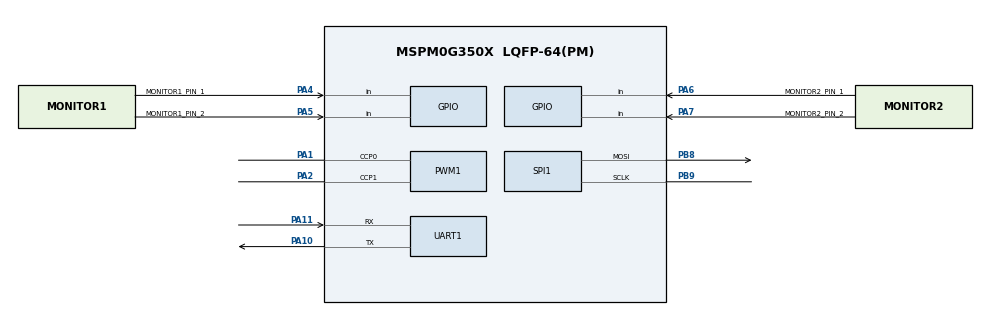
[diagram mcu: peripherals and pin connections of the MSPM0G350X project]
/**
 * These arguments were used when this file was generated. They will be automatically applied on subsequent loads
 * via the GUI or CLI. Run CLI with '--help' for additional information on how to override these arguments.
 * @cliArgs --device "MSPM0G350X" --package "LQFP-64(PM)" --part "Default" --product "mspm0_sdk@2.01.00.03"
 * @versions {"tool":"1.20.0+3587"}
 */

/**
 * Import the modules used in this configuration.
 */
const GPIO   = scripting.addModule("/ti/driverlib/GPIO", {}, false);
const GPIO1  = GPIO.addInstance();
const GPIO2  = GPIO.addInstance();
const GPIO3  = GPIO.addInstance();
const GPIO4  = GPIO.addInstance();
const GPIO5  = GPIO.addInstance();
const PWM    = scripting.addModule("/ti/driverlib/PWM", {}, false);
const PWM1   = PWM.addInstance();
const SPI    = scripting.addModule("/ti/driverlib/SPI", {}, false);
const SPI1   = SPI.addInstance();
const SYSCTL = scripting.addModule("/ti/driverlib/SYSCTL");
const TIMER  = scripting.addModule("/ti/driverlib/TIMER", {}, false);
const TIMER1 = TIMER.addInstance();
const UART   = scripting.addModule("/ti/driverlib/UART", {}, false);
const UART1  = UART.addInstance();

/**
 * Write custom configuration values to the imported modules.
 */
GPIO1.$name                          = "GPIO_LED";
GPIO1.associatedPins[0].$name        = "LED";
GPIO1.associatedPins[0].assignedPort = "PORTA";
GPIO1.associatedPins[0].assignedPin  = "3";

const Board = scripting.addModule("/ti/driverlib/Board", {}, false);

GPIO2.$name                          = "GPIO_OLED";
GPIO2.associatedPins.create(2);
GPIO2.associatedPins[0].$name        = "PIN_SCL";
GPIO2.associatedPins[0].assignedPort = "PORTA";
GPIO2.associatedPins[0].assignedPin  = "12";
GPIO2.associatedPins[1].$name        = "PIN_SDA";
GPIO2.associatedPins[1].assignedPort = "PORTA";
GPIO2.associatedPins[1].assignedPin  = "13";

GPIO3.$name                          = "GPIO_LCD";
GPIO3.associatedPins.create(4);
GPIO3.associatedPins[0].assignedPort = "PORTA";
GPIO3.associatedPins[0].assignedPin  = "27";
GPIO3.associatedPins[0].$name        = "ST7789_RST";
GPIO3.associatedPins[0].initialValue = "SET";
GPIO3.associatedPins[1].$name        = "ST7789_A0";
GPIO3.associatedPins[1].assignedPort = "PORTA";
GPIO3.associatedPins[1].assignedPin  = "26";
GPIO3.associatedPins[1].initialValue = "SET";
GPIO3.associatedPins[2].$name        = "ST7789_CS";
GPIO3.associatedPins[2].assignedPort = "PORTA";
GPIO3.associatedPins[2].assignedPin  = "25";
GPIO3.associatedPins[2].initialValue = "SET";
GPIO3.associatedPins[3].$name        = "ST7789_BL";
GPIO3.associatedPins[3].assignedPort = "PORTA";
GPIO3.associatedPins[3].assignedPin  = "24";
GPIO3.associatedPins[3].initialValue = "SET";

GPIO4.$name                          = "GPIO_SPI_OLED";
GPIO4.associatedPins.create(4);
GPIO4.associatedPins[0].$name        = "CLK";
GPIO4.associatedPins[0].assignedPort = "PORTA";
GPIO4.associatedPins[0].assignedPin  = "14";
GPIO4.associatedPins[1].$name        = "SDA";
GPIO4.associatedPins[1].assignedPort = "PORTA";
GPIO4.associatedPins[1].assignedPin  = "15";
GPIO4.associatedPins[2].$name        = "CS";
GPIO4.associatedPins[2].assignedPort = "PORTA";
GPIO4.associatedPins[2].assignedPin  = "16";
GPIO4.associatedPins[3].$name        = "DC";
GPIO4.associatedPins[3].assignedPort = "PORTA";
GPIO4.associatedPins[3].assignedPin  = "17";

GPIO5.$name                         = "GPIO_ENCODER";
GPIO5.associatedPins.create(4);
GPIO5.associatedPins[0].direction   = "INPUT";
GPIO5.associatedPins[0].interruptEn = true;
GPIO5.associatedPins[0].polarity    = "RISE";
GPIO5.associatedPins[0].$name       = "MONITOR1_PIN_1";
GPIO5.associatedPins[0].pin.$assign = "PA4";
GPIO5.associatedPins[1].$name       = "MONITOR1_PIN_2";
GPIO5.associatedPins[1].direction   = "INPUT";
GPIO5.associatedPins[1].interruptEn = true;
GPIO5.associatedPins[1].polarity    = "RISE";
GPIO5.associatedPins[1].pin.$assign = "PA5";
GPIO5.associatedPins[2].$name       = "MONITOR2_PIN_1";
GPIO5.associatedPins[2].direction   = "INPUT";
GPIO5.associatedPins[2].interruptEn = true;
GPIO5.associatedPins[2].polarity    = "RISE";
GPIO5.associatedPins[2].pin.$assign = "PA6";
GPIO5.associatedPins[3].$name       = "MONITOR2_PIN_2";
GPIO5.associatedPins[3].direction   = "INPUT";
GPIO5.associatedPins[3].interruptEn = true;
GPIO5.associatedPins[3].polarity    = "RISE";
GPIO5.associatedPins[3].pin.$assign = "PA7";

PWM1.$name                      = "PWM_0";
PWM1.clockPrescale              = 32;
PWM1.pwmMode                    = "EDGE_ALIGN_UP";
PWM1.peripheral.ccp0Pin.$assign = "PA1";
PWM1.peripheral.ccp1Pin.$assign = "PA2";
PWM1.PWM_CHANNEL_0.$name        = "ti_driverlib_pwm_PWMTimerCC0";
PWM1.PWM_CHANNEL_0.dutyCycle    = 50;
PWM1.PWM_CHANNEL_1.$name        = "ti_driverlib_pwm_PWMTimerCC1";
PWM1.PWM_CHANNEL_1.dutyCycle    = 30;
PWM1.ccp0PinConfig.$name        = "ti_driverlib_gpio_GPIOPinGeneric4";
PWM1.ccp1PinConfig.$name        = "ti_driverlib_gpio_GPIOPinGeneric5";

SPI1.$name                              = "SPI1";
SPI1.phase                              = "1";
SPI1.frameFormat                        = "MOTO3";
SPI1.polarity                           = "1";
SPI1.direction                          = "PICO";
SPI1.peripheral.sclkPin.$assign         = "PB9";
SPI1.peripheral.mosiPin.$assign         = "PB8";
SPI1.sclkPinConfig.$name                = "ti_driverlib_gpio_GPIOPinGeneric2";
SPI1.sclkPinConfig.direction            = scripting.forceWrite("OUTPUT");
SPI1.sclkPinConfig.onlyInternalResistor = scripting.forceWrite(false);
SPI1.sclkPinConfig.passedPeripheralType = scripting.forceWrite("Digital");
SPI1.mosiPinConfig.$name                = "ti_driverlib_gpio_GPIOPinGeneric3";
SPI1.mosiPinConfig.direction            = scripting.forceWrite("OUTPUT");
SPI1.mosiPinConfig.hideOutputInversion  = scripting.forceWrite(false);
SPI1.mosiPinConfig.onlyInternalResistor = scripting.forceWrite(false);
SPI1.mosiPinConfig.passedPeripheralType = scripting.forceWrite("Digital");

SYSCTL.forceDefaultClkConfig = true;

TIMER1.$name              = "TIMER_0";
TIMER1.timerClkDiv        = 2;
TIMER1.timerClkPrescale   = 160;
TIMER1.timerMode          = "PERIODIC";
TIMER1.timerPeriod        = "10ms";
TIMER1.interrupts         = ["ZERO"];
TIMER1.peripheral.$assign = "TIMG0";

UART1.$name                    = "UART_0";
UART1.enabledInterrupts        = ["RX"];
UART1.targetBaudRate           = 115200;
UART1.peripheral.rxPin.$assign = "PA11";
UART1.peripheral.txPin.$assign = "PA10";
UART1.txPinConfig.$name        = "ti_driverlib_gpio_GPIOPinGeneric0";
UART1.rxPinConfig.$name        = "ti_driverlib_gpio_GPIOPinGeneric1";

/**
 * Pinmux solution for unlocked pins/peripherals. This ensures that minor changes to the automatic solver in a future
 * version of the tool will not impact the pinmux you originally saw.  These lines can be completely deleted in order to
 * re-solve from scratch.
 */
GPIO1.associatedPins[0].pin.$suggestSolution = "PA3";
Board.peripheral.$suggestSolution            = "DEBUGSS";
Board.peripheral.swclkPin.$suggestSolution   = "PA20";
Board.peripheral.swdioPin.$suggestSolution   = "PA19";
GPIO2.associatedPins[0].pin.$suggestSolution = "PA12";
GPIO2.associatedPins[1].pin.$suggestSolution = "PA13";
GPIO3.associatedPins[0].pin.$suggestSolution = "PA27";
GPIO3.associatedPins[1].pin.$suggestSolution = "PA26";
GPIO3.associatedPins[2].pin.$suggestSolution = "PA25";
GPIO3.associatedPins[3].pin.$suggestSolution = "PA24";
GPIO4.associatedPins[0].pin.$suggestSolution = "PA14";
GPIO4.associatedPins[1].pin.$suggestSolution = "PA15";
GPIO4.associatedPins[2].pin.$suggestSolution = "PA16";
GPIO4.associatedPins[3].pin.$suggestSolution = "PA17";
PWM1.peripheral.$suggestSolution             = "TIMG8";
SPI1.peripheral.$suggestSolution             = "SPI1";
SYSCTL.peripheral.$suggestSolution           = "SYSCTL";
UART1.peripheral.$suggestSolution            = "UART0";
